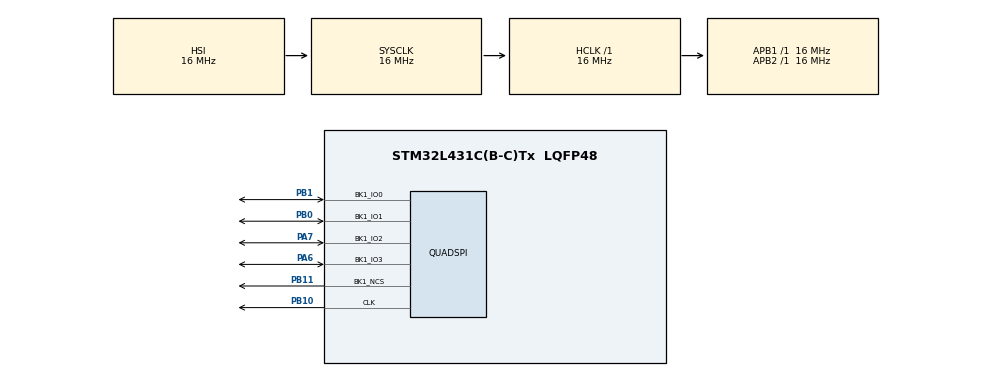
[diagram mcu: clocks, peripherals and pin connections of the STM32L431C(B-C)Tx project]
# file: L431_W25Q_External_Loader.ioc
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Mcu.Family=STM32L4
Mcu.Name=STM32L431C(B-C)Tx
Mcu.Package=LQFP48
NVIC.PriorityGroup=NVIC_PRIORITYGROUP_4
PA13\ (JTMS-SWDIO).Mode=Serial_Wire
PA13\ (JTMS-SWDIO).Signal=SYS_JTMS-SWDIO
PA14\ (JTCK-SWCLK).Mode=Serial_Wire
PA14\ (JTCK-SWCLK).Signal=SYS_JTCK-SWCLK
PA6.Mode=Single Bank 1
PA6.Signal=QUADSPI_BK1_IO3
PA7.Mode=Single Bank 1
PA7.Signal=QUADSPI_BK1_IO2
PB0.Mode=Single Bank 1
PB0.Signal=QUADSPI_BK1_IO1
PB1.Mode=Single Bank 1
PB1.Signal=QUADSPI_BK1_IO0
PB10.Mode=Single Bank 1
PB10.Signal=QUADSPI_CLK
PB11.Mode=Single Bank 1
PB11.Signal=QUADSPI_BK1_NCS
ProjectManager.HeapSize=0x200
ProjectManager.StackSize=0x400
ProjectManager.TargetToolchain=STM32CubeIDE
QUADSPI.ClockPrescaler=1
QUADSPI.FifoThreshold=4
QUADSPI.FlashSize=23
QUADSPI.SampleShifting=QSPI_SAMPLE_SHIFTING_HALFCYCLE
RCC.ADCFreq_Value=64000000
RCC.AHBFreq_Value=16000000
RCC.APB1Freq_Value=16000000
RCC.APB1TimFreq_Value=16000000
RCC.APB2Freq_Value=16000000
RCC.APB2TimFreq_Value=16000000
RCC.CortexFreq_Value=16000000
RCC.HCLKFreq_Value=16000000
RCC.HSE_VALUE=8000000
RCC.HSI48_VALUE=48000000
RCC.HSI_VALUE=16000000
RCC.LSE_VALUE=32768
RCC.MSI_VALUE=4000000
RCC.PLLN=10
RCC.PLLSourceVirtual=RCC_PLLSOURCE_HSI
RCC.SYSCLKFreq_VALUE=16000000
RCC.SYSCLKSource=RCC_SYSCLKSOURCE_HSI
RCC.VCOOutputFreq_Value=160000000
board=custom

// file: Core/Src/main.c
/* USER CODE BEGIN Header */
/**
 ******************************************************************************
 * @file           : main.c
 * @brief          : Main program body
 ******************************************************************************
 * @attention
 *
 * Copyright (c) 2024 STMicroelectronics.
 * All rights reserved.
 *
 * This software is licensed under terms that can be found in the LICENSE file
 * in the root directory of this software component.
 * If no LICENSE file comes with this software, it is provided AS-IS.
 *
 ******************************************************************************
 */
/* USER CODE END Header */
#include "main.h"
#include "quadspi.h"
#include "gpio.h"

void SystemClock_Config(void);

int main(void)
{

  /* MCU Configuration--------------------------------------------------------*/

  /* Reset of all peripherals, Initializes the Flash interface and the Systick. */
  HAL_Init();

  /* Configure the system clock */
  SystemClock_Config();

  /* Initialize all configured peripherals */
  MX_GPIO_Init();
  MX_QUADSPI_Init();
  /* USER CODE BEGIN 2 */

	CSP_QUADSPI_Init();

	if (CSP_QSPI_EnableMemoryMappedMode() != HAL_OK) {
		while (1);
	}

  /* USER CODE END 2 */

  /* Infinite loop */
	while (1) {

	}
}

void SystemClock_Config(void)
{
  RCC_OscInitTypeDef RCC_OscInitStruct = {0};
  RCC_ClkInitTypeDef RCC_ClkInitStruct = {0};

  /** Configure the main internal regulator output voltage
  */
  if (HAL_PWREx_ControlVoltageScaling(PWR_REGULATOR_VOLTAGE_SCALE1) != HAL_OK)
  {
    Error_Handler();
  }

  /** Initializes the RCC Oscillators according to the specified parameters
  * in the RCC_OscInitTypeDef structure.
  */
  RCC_OscInitStruct.OscillatorType = RCC_OSCILLATORTYPE_HSI;
  RCC_OscInitStruct.HSIState = RCC_HSI_ON;
  RCC_OscInitStruct.HSICalibrationValue = RCC_HSICALIBRATION_DEFAULT;
  RCC_OscInitStruct.PLL.PLLState = RCC_PLL_NONE;
  if (HAL_RCC_OscConfig(&RCC_OscInitStruct) != HAL_OK)
  {
    Error_Handler();
  }

  /** Initializes the CPU, AHB and APB buses clocks
  */
  RCC_ClkInitStruct.ClockType = RCC_CLOCKTYPE_HCLK|RCC_CLOCKTYPE_SYSCLK
                              |RCC_CLOCKTYPE_PCLK1|RCC_CLOCKTYPE_PCLK2;
  RCC_ClkInitStruct.SYSCLKSource = RCC_SYSCLKSOURCE_HSI;
  RCC_ClkInitStruct.AHBCLKDivider = RCC_SYSCLK_DIV1;
  RCC_ClkInitStruct.APB1CLKDivider = RCC_HCLK_DIV1;
  RCC_ClkInitStruct.APB2CLKDivider = RCC_HCLK_DIV1;

  if (HAL_RCC_ClockConfig(&RCC_ClkInitStruct, FLASH_LATENCY_0) != HAL_OK)
  {
    Error_Handler();
  }
}

void Error_Handler(void)
{
	__disable_irq();
	while (1) {
	}
}
